# ATSAMD20E15 register map
Vendor: Atmel Corporation; Series: SAMD20; File version: D
CPU: CM0+ r0p1, little endian, no MPU, no FPU, VTOR, 2 interrupt priority bits
Registers are 8-bit, read-write, reset 0x0 unless marked. A register's access mark holds for its fields unless they carry their own. Offsets are from the block's base; [hi:lo] are bit positions; {n}, {i} and the like mark numbered series; 'fields as' and 'values as' point back to an identical list.

## PORT — Port Module
Base 0x41004400
0x00 DIR 32-bit — Data Direction
  [31:0] DIR — Port Data Direction
0x04 DIRCLR 32-bit — Data Direction Clear
  [31:0] DIRCLR — Port Data Direction Clear
0x08 DIRSET 32-bit — Data Direction Set
  [31:0] DIRSET — Port Data Direction Set
0x0C DIRTGL 32-bit — Data Direction Toggle
  [31:0] DIRTGL — Port Data Direction Toggle
0x10 OUT 32-bit — Data Output Value
  [31:0] OUT — Port Data Output Value
0x14 OUTCLR 32-bit — Data Output Value Clear
  [31:0] OUTCLR — Port Data Output Value Clear
0x18 OUTSET 32-bit — Data Output Value Set
  [31:0] OUTSET — Port Data Output Value Set
0x1C OUTTGL 32-bit — Data Output Value Toggle
  [31:0] OUTTGL — Port Data Output Value Toggle
0x20 IN 32-bit ro — Data Input Value
  [31:0] IN — Port Data Input Value
0x24 CTRL 32-bit — Control
  [31:0] SAMPLING wo — Input Sampling Mode
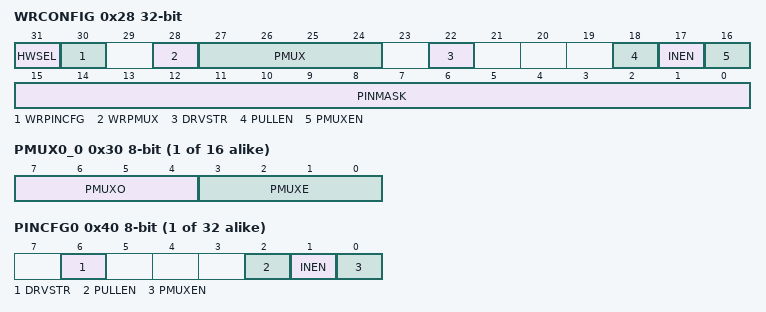
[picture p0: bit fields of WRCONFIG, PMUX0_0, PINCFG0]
0x28 WRCONFIG 32-bit wo — Write Configuration
  [31] HWSEL — Half-Word Select
  [30] WRPINCFG — Write PINCFG
  [28] WRPMUX — Write PMUX
  [27:24] PMUX — Peripheral Multiplexing
  [22] DRVSTR — Output Driver Strength Selection
  [18] PULLEN — Pull Enable
  [17] INEN — Input Enable
  [16] PMUXEN — Peripheral Multiplexer Enable
  [15:0] PINMASK — Pin Mask for Multiple Pin Configuration
{0x30+i} PMUX0_{i} (i=0..15) — Peripheral Multiplexing n - Group 0
  [7:4] PMUXO — Peripheral Multiplexing Odd
    0=A (Peripheral function A selected); 1=B (Peripheral function B selected); 2=C (Peripheral function C selected); 3=D (Peripheral function D selected); 4=E (Peripheral function E selected); 5=F (Peripheral function F selected); 6=G (Peripheral function G selected); 7=H (Peripheral function H selected)
  [3:0] PMUXE — Peripheral Multiplexing Even
    values as PMUXO
{0x40+i} PINCFG{i} (i=0..31) — Pin Configuration n - Group 0
  [6] DRVSTR wo — Output Driver Strength Selection
  [2] PULLEN — Pull Enable
  [1] INEN — Input Enable
  [0] PMUXEN — Peripheral Multiplexer Enable

## SERCOM0 — Serial Communication Interface 0
Base 0x42000800
Same registers: SERCOM1 0x42000C00, SERCOM2 0x42001000, SERCOM3 0x42001400
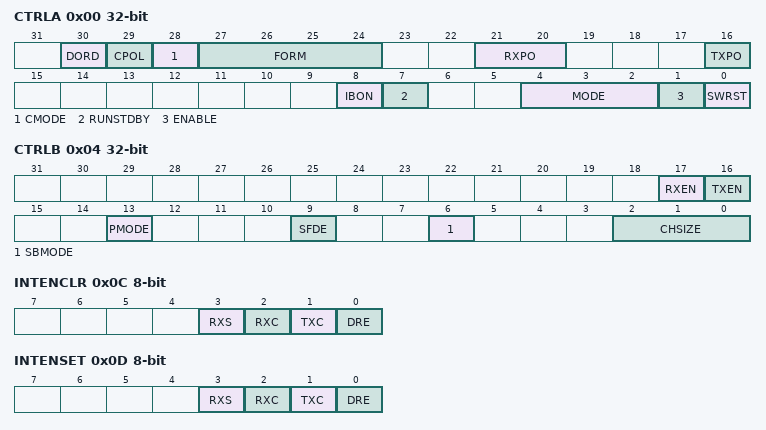
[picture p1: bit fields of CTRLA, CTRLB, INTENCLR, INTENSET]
0x00 CTRLA 32-bit — USART Control A
  [30] DORD — Data Order
  [29] CPOL — Clock Polarity
  [28] CMODE — Communication Mode
  [27:24] FORM — Frame Format
    0=USART frame; 1=USART frame with parity
  [21:20] RXPO — Receive Data Pinout
    {v}=PAD{v} (SERCOM_PAD{v}) (v=0..3)
  [16] TXPO — Transmit Data Pinout
    0=PAD0 (TXD at PAD0, XCK at PAD1); 1=PAD2 (TXD at PAD2, XCK at PAD3)
  [8] IBON — Immediate Buffer Overflow Notification
  [7] RUNSTDBY — Run In Standby
  [4:2] MODE — Operating Mode
    0=USART_EXT_CLK (USART mode with external clock); 1=USART_INT_CLK (USART mode with internal clock); 2=SPI_SLAVE (SPI mode with external clock); 3=SPI_MASTER (SPI mode with internal clock); 4=I2C_SLAVE (I2C mode with external clock); 5=I2C_MASTER (I2C mode with internal clock)
  [1] ENABLE
  [0] SWRST — Software Reset
0x04 CTRLB 32-bit — USART Control B
  [17] RXEN — Receiver Enable
  [16] TXEN — Transmitter Enable
  [13] PMODE — Parity Mode
  [9] SFDE — Start of Frame Detection Enable
  [6] SBMODE — Stop Bit Mode
  [2:0] CHSIZE — Character Size
0x08 DBGCTRL — USART Debug Control
  [0] DBGSTOP — Debug Stop Mode
0x0A BAUD 16-bit — USART Baud
  [15:0] BAUD — Baud Value
0x0C INTENCLR — USART Interrupt Enable Clear
  [3] RXS — Receive Start Interrupt Disable
  [2] RXC — Receive Complete Interrupt Enable
  [1] TXC — Transmit Complete Interrupt Enable
  [0] DRE — Data Register Empty Interrupt Enable
0x0D INTENSET — USART Interrupt Enable Set
  [3] RXS — Receive Start Interrupt Enable
  [2] RXC — Receive Complete Interrupt Enable
  [1] TXC — Transmit Complete Interrupt Enable
  [0] DRE — Data Register Empty Interrupt Enable
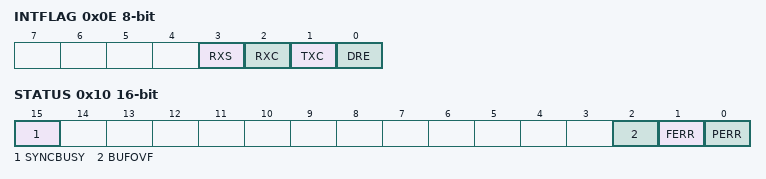
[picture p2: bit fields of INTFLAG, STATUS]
0x0E INTFLAG — USART Interrupt Flag Status and Clear
  [3] RXS wo — Receive Start Interrupt
  [2] RXC ro — Receive Complete
  [1] TXC — Transmit Complete
  [0] DRE ro — Data Register Empty
0x10 STATUS 16-bit — USART Status
  [15] SYNCBUSY ro — Synchronization Busy
  [2] BUFOVF — Buffer Overflow
  [1] FERR — Frame Error
  [0] PERR — Parity Error
0x18 DATA 16-bit — USART Data
  [8:0] DATA
